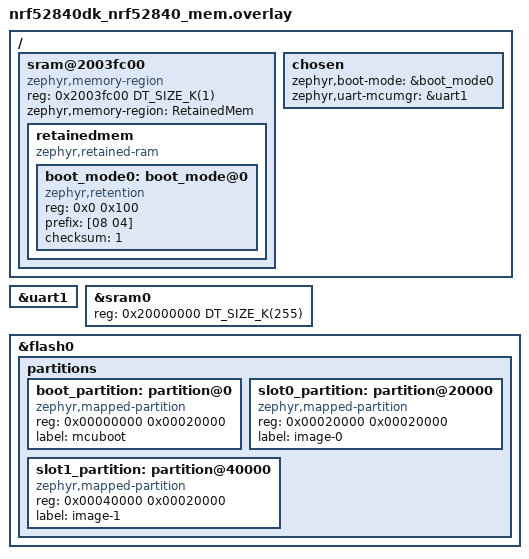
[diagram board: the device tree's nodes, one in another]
/* SPDX-License-Identifier: Apache-2.0 */

/ {
	sram@2003fc00 {
		compatible = "zephyr,memory-region", "mmio-sram";
		reg = <0x2003fc00 DT_SIZE_K(1)>;
		zephyr,memory-region = "RetainedMem";
		status = "okay";

		retainedmem {
			compatible = "zephyr,retained-ram";
			#address-cells = <1>;
			#size-cells = <1>;
			status = "okay";

			boot_mode0: boot_mode@0 {
				compatible = "zephyr,retention";
				reg = <0x0 0x100>;
				prefix = [08 04];
				checksum = <1>;
				status = "okay";
			};
		};
	};

	chosen {
		zephyr,boot-mode = &boot_mode0;
		zephyr,uart-mcumgr = &uart1;
	};
};

&uart1 {
	status = "okay";
};

/delete-node/ &gpregret1;
/delete-node/ &gpregret2;
/delete-node/ &boot_partition;
/delete-node/ &slot0_partition;
/delete-node/ &slot1_partition;

&sram0 {
	reg = <0x20000000 DT_SIZE_K(255)>;
};

&flash0 {
	partitions {
		boot_partition: partition@0 {
			compatible = "zephyr,mapped-partition";
			reg = <0x00000000 0x00020000>;
			label = "mcuboot";
		};

		slot0_partition: partition@20000 {
			compatible = "zephyr,mapped-partition";
			reg = <0x00020000 0x00020000>;
			label = "image-0";
		};

		slot1_partition: partition@40000 {
			compatible = "zephyr,mapped-partition";
			reg = <0x00040000 0x00020000>;
			label = "image-1";
		};
	};
};
